# ATSAMV70N19 register map
Vendor: Microchip Technology; File version: 0
CPU: CM7 r1p1, little endian, no MPU, no FPU, 0x3 interrupt priority bits, 0x0 interrupts
Registers are 32-bit, read-write, reset 0x0 unless marked. A register's access mark holds for its fields unless they carry their own. Offsets are from the block's base; [hi:lo] are bit positions; 'fields as' and 'values as' point back to an identical list.

## TC0 — Timer Counter
Base 0x4000C000; register names take the prefix TC_
0xC0 TC_BCR wo — Block Control Register
  [0] SYNC — Synchro Command
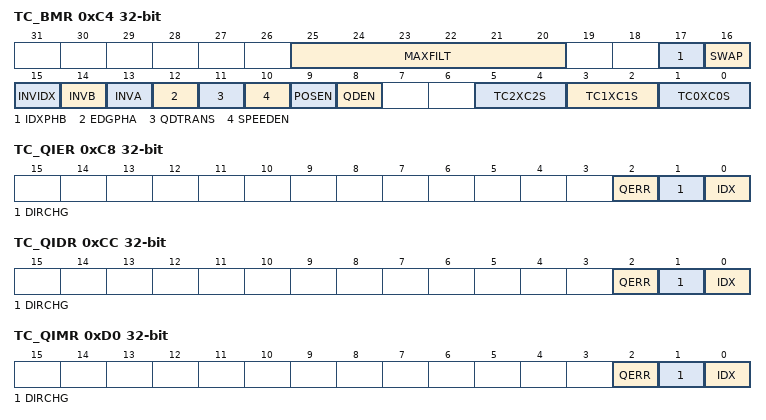
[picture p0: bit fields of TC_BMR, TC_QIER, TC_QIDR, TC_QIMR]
0xC4 TC_BMR — Block Mode Register
  [25:20] MAXFILT — Maximum Filter
  [17] IDXPHB — Index Pin is PHB Pin
  [16] SWAP — Swap PHA and PHB
  [15] INVIDX — Inverted Index
  [14] INVB — Inverted PHB
  [13] INVA — Inverted PHA
  [12] EDGPHA — Edge on PHA Count Mode
  [11] QDTRANS — Quadrature Decoding Transparent
  [10] SPEEDEN — Speed Enabled
  [9] POSEN — Position Enabled
  [8] QDEN — Quadrature Decoder Enabled
  [5:4] TC2XC2S — External Clock Signal 2 Selection
    0=TCLK2 (Signal connected to XC2: TCLK2); 2=TIOA0 (Signal connected to XC2: TIOA0); 3=TIOA1 (Signal connected to XC2: TIOA1)
  [3:2] TC1XC1S — External Clock Signal 1 Selection
    0=TCLK1 (Signal connected to XC1: TCLK1); 2=TIOA0 (Signal connected to XC1: TIOA0); 3=TIOA2 (Signal connected to XC1: TIOA2)
  [1:0] TC0XC0S — External Clock Signal 0 Selection
    0=TCLK0 (Signal connected to XC0: TCLK0); 2=TIOA1 (Signal connected to XC0: TIOA1); 3=TIOA2 (Signal connected to XC0: TIOA2)
0xC8 TC_QIER wo — QDEC Interrupt Enable Register
  [2] QERR — Quadrature Error
  [1] DIRCHG — Direction Change
  [0] IDX — Index
0xCC TC_QIDR wo — QDEC Interrupt Disable Register
  fields as TC_QIER
0xD0 TC_QIMR ro — QDEC Interrupt Mask Register
  fields as TC_QIER
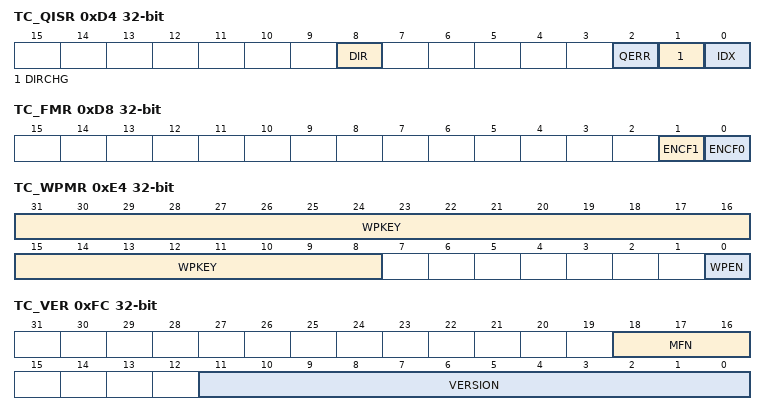
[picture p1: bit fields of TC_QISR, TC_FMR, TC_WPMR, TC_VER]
0xD4 TC_QISR ro — QDEC Interrupt Status Register
  [8] DIR — Direction
  [2] QERR — Quadrature Error
  [1] DIRCHG — Direction Change
  [0] IDX — Index
0xD8 TC_FMR — Fault Mode Register
  [1] ENCF1 — Enable Compare Fault Channel 1
  [0] ENCF0 — Enable Compare Fault Channel 0
0xE4 TC_WPMR — Write Protection Mode Register
  [31:8] WPKEY — Write Protection Key
    0x54494D=PASSWD (Writing any other value in this field aborts the write operation of the WPEN bit.Always reads as 0.)
  [0] WPEN — Write Protection Enable
0xFC TC_VER ro — Version Register
  [18:16] MFN — Metal Fix Number
  [11:0] VERSION — Version of the Hardware Module

## TC1 — Timer Counter
Base 0x40010000; register names take the prefix TC_
Registers as TC0; these are added or differ:
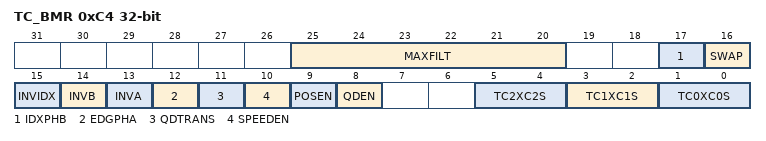
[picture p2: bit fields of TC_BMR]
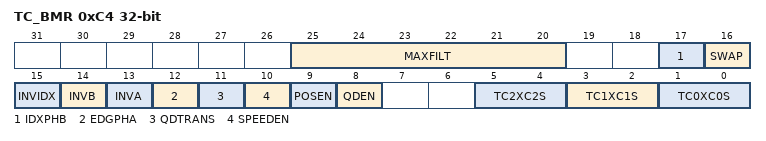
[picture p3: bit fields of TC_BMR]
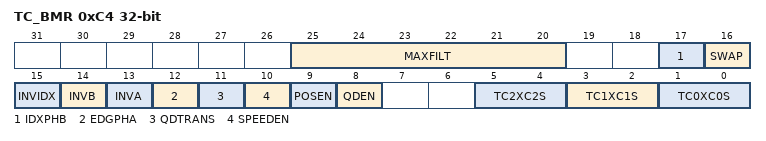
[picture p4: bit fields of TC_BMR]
0xC4 TC_BMR — Block Mode Register
  fields as TC0.TC_BMR

## TC2 — Timer Counter
Base 0x40014000; register names take the prefix TC_
Registers as TC0; these are added or differ:
0xC4 TC_BMR — Block Mode Register
  fields as TC0.TC_BMR

## TC3 — Timer Counter
Base 0x40054000; register names take the prefix TC_
Registers as TC0; these are added or differ:
0xC4 TC_BMR — Block Mode Register
  fields as TC0.TC_BMR

## TRNG — True Random Number Generator
Base 0x40070000; register names take the prefix TRNG_
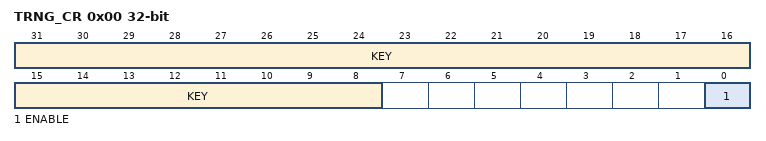
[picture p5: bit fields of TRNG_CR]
0x00 TRNG_CR wo — Control Register
  [31:8] KEY — Security Key
    0x524E47=PASSWD (Writing any other value in this field aborts the write operation.)
  [0] ENABLE — Enables the TRNG to Provide Random Values
0x10 TRNG_IER wo — Interrupt Enable Register
  [0] DATRDY — Data Ready Interrupt Enable
0x14 TRNG_IDR wo — Interrupt Disable Register
  [0] DATRDY — Data Ready Interrupt Disable
0x18 TRNG_IMR ro — Interrupt Mask Register
  [0] DATRDY — Data Ready Interrupt Mask
0x1C TRNG_ISR ro — Interrupt Status Register
  [0] DATRDY — Data Ready
0x50 TRNG_ODATA ro — Output Data Register
  [31:0] ODATA — Output Data

## UTMI — USB Transmitter Interface Macrocell
Base 0x400E0400; register names take the prefix UTMI_
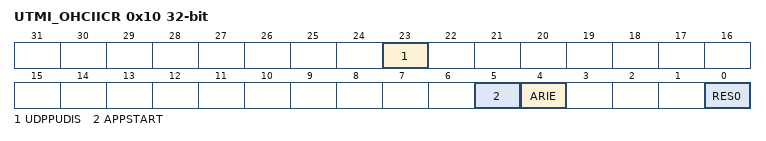
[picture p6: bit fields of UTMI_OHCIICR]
0x10 UTMI_OHCIICR — OHCI Interrupt Configuration Register
  [23] UDPPUDIS — USB Device Pull-up Disable
  [5] APPSTART
  [4] ARIE — OHCI Asynchronous Resume Interrupt Enable
  [0] RES0 — USB PORTx Reset
0x30 UTMI_CKTRIM — UTMI Clock Trimming Register
  [1:0] FREQ — UTMI Reference Clock Frequency
    0=XTAL12 (12 MHz reference clock); 1=XTAL16 (16 MHz reference clock)
